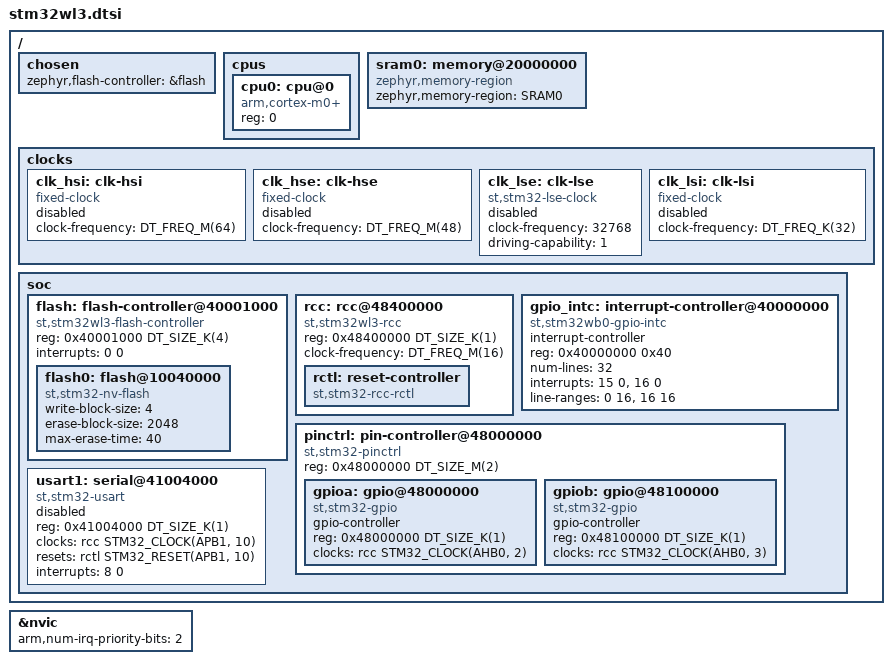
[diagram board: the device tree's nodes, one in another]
/*
 * Copyright (c) 2024 STMicroelectronics
 * Copyright (c) 2026 Anders Frandsen <anfran@anfran.dk>
 *
 * SPDX-License-Identifier: Apache-2.0
 */

#include <arm/armv6-m.dtsi>
#include <zephyr/dt-bindings/gpio/gpio.h>
#include <zephyr/dt-bindings/clock/stm32wl3_clock.h>
#include <zephyr/dt-bindings/reset/stm32wl3_reset.h>
#include <freq.h>
#include <mem.h>

/ {
	chosen {
		zephyr,flash-controller = &flash;
	};

	cpus {
		#address-cells = <1>;
		#size-cells = <0>;

		cpu0: cpu@0 {
			device_type = "cpu";
			compatible = "arm,cortex-m0+";
			reg = <0>;
		};
	};

	sram0: memory@20000000 {
		compatible = "zephyr,memory-region", "mmio-sram";
		zephyr,memory-region = "SRAM0";
	};

	clocks {
		clk_hsi: clk-hsi {
			#clock-cells = <0>;
			compatible = "fixed-clock";
			clock-frequency = <DT_FREQ_M(64)>;   /* HSI: 64 MHz RC (RC64MPLL) */
			status = "disabled";
		};

		clk_hse: clk-hse {
			#clock-cells = <0>;
			compatible = "fixed-clock";
			clock-frequency = <DT_FREQ_M(48)>;   /* HSE: 48 MHz crystal (radio) */
			status = "disabled";
		};

		clk_lse: clk-lse {
			#clock-cells = <0>;
			compatible = "st,stm32-lse-clock";
			clock-frequency = <32768>;
			driving-capability = <1>;
			status = "disabled";
		};

		clk_lsi: clk-lsi {
			#clock-cells = <0>;
			compatible = "fixed-clock";
			clock-frequency = <DT_FREQ_K(32)>;
			status = "disabled";
		};
	};

	soc {
		flash: flash-controller@40001000 {
			compatible = "st,stm32wl3-flash-controller", "st,stm32-flash-controller";
			reg = <0x40001000 DT_SIZE_K(4)>;
			interrupts = <0 0>;
			#address-cells = <1>;
			#size-cells = <1>;
			ranges;

			/* 'reg' (flash base + size) is added per-die in stm32wl33.dtsi */
			flash0: flash@10040000 {
				compatible = "st,stm32-nv-flash", "soc-nv-flash";
				#address-cells = <1>;
				#size-cells = <1>;
				write-block-size = <4>;
				erase-block-size = <2048>;
				max-erase-time = <40>;
			};
		};

		rcc: rcc@48400000 {
			compatible = "st,stm32wl3-rcc";
			reg = <0x48400000 DT_SIZE_K(1)>;
			#clock-cells = <2>;
			clock-frequency = <DT_FREQ_M(16)>;   /* reset CLK_SYS = HSI 64 MHz / 4 */

			rctl: reset-controller {
				compatible = "st,stm32-rcc-rctl";
				#reset-cells = <1>;
			};
		};

		gpio_intc: interrupt-controller@40000000 {
			compatible = "st,stm32wb0-gpio-intc";
			interrupt-controller;
			#interrupt-cells = <1>;
			#address-cells = <1>;
			reg = <0x40000000 0x40>;
			num-lines = <32>;
			interrupts = <15 0>, <16 0>;
			interrupt-names = "gpioa", "gpiob";
			line-ranges = <0 16>, <16 16>;
		};

		pinctrl: pin-controller@48000000 {
			compatible = "st,stm32-pinctrl";
			#address-cells = <1>;
			#size-cells = <1>;
			reg = <0x48000000 DT_SIZE_M(2)>;

			gpioa: gpio@48000000 {
				compatible = "st,stm32-gpio";
				gpio-controller;
				#gpio-cells = <2>;
				reg = <0x48000000 DT_SIZE_K(1)>;
				clocks = <&rcc STM32_CLOCK(AHB0, 2)>;
			};

			gpiob: gpio@48100000 {
				compatible = "st,stm32-gpio";
				gpio-controller;
				#gpio-cells = <2>;
				reg = <0x48100000 DT_SIZE_K(1)>;
				clocks = <&rcc STM32_CLOCK(AHB0, 3)>;
			};
		};

		usart1: serial@41004000 {
			compatible = "st,stm32-usart", "st,stm32-uart";
			reg = <0x41004000 DT_SIZE_K(1)>;
			clocks = <&rcc STM32_CLOCK(APB1, 10)>;
			resets = <&rctl STM32_RESET(APB1, 10)>;
			interrupts = <8 0>;
			status = "disabled";
		};
	};
};

&nvic {
	arm,num-irq-priority-bits = <2>;
};
